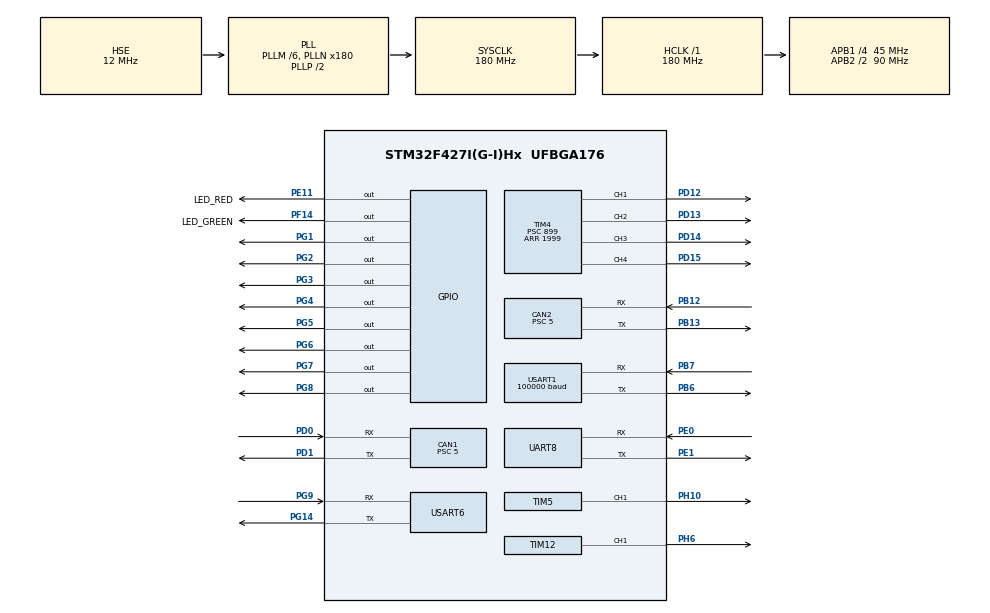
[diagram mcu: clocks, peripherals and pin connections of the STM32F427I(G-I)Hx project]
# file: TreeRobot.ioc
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CAN1.BS1=CAN_BS1_3TQ
CAN1.BS2=CAN_BS2_5TQ
CAN1.CalculateBaudRate=1000000
CAN1.CalculateTimeBit=999.99
CAN1.CalculateTimeQuantum=111.11111111111111
CAN1.Prescaler=5
CAN2.BS1=CAN_BS1_3TQ
CAN2.BS2=CAN_BS2_5TQ
CAN2.CalculateBaudRate=1000000
CAN2.CalculateTimeBit=999.99
CAN2.CalculateTimeQuantum=111.11111111111111
CAN2.Prescaler=5
CAN2.SJW=CAN_SJW_4TQ
Dma.Request0=USART1_RX
Dma.Request1=USART6_RX
Dma.Request2=UART8_RX
Dma.UART8_RX.2.Direction=DMA_PERIPH_TO_MEMORY
Dma.UART8_RX.2.FIFOMode=DMA_FIFOMODE_DISABLE
Dma.UART8_RX.2.Instance=DMA1_Stream6
Dma.UART8_RX.2.MemDataAlignment=DMA_MDATAALIGN_BYTE
Dma.UART8_RX.2.MemInc=DMA_MINC_ENABLE
Dma.UART8_RX.2.Mode=DMA_CIRCULAR
Dma.UART8_RX.2.PeriphDataAlignment=DMA_PDATAALIGN_BYTE
Dma.UART8_RX.2.PeriphInc=DMA_PINC_DISABLE
Dma.UART8_RX.2.Priority=DMA_PRIORITY_LOW
Dma.USART1_RX.0.Direction=DMA_PERIPH_TO_MEMORY
Dma.USART1_RX.0.FIFOMode=DMA_FIFOMODE_DISABLE
Dma.USART1_RX.0.Instance=DMA2_Stream2
Dma.USART1_RX.0.MemDataAlignment=DMA_MDATAALIGN_BYTE
Dma.USART1_RX.0.MemInc=DMA_MINC_ENABLE
Dma.USART1_RX.0.Mode=DMA_CIRCULAR
Dma.USART1_RX.0.PeriphDataAlignment=DMA_PDATAALIGN_BYTE
Dma.USART1_RX.0.PeriphInc=DMA_PINC_DISABLE
Dma.USART1_RX.0.Priority=DMA_PRIORITY_LOW
Dma.USART6_RX.1.Direction=DMA_PERIPH_TO_MEMORY
Dma.USART6_RX.1.FIFOMode=DMA_FIFOMODE_DISABLE
Dma.USART6_RX.1.Instance=DMA2_Stream1
Dma.USART6_RX.1.MemDataAlignment=DMA_MDATAALIGN_BYTE
Dma.USART6_RX.1.MemInc=DMA_MINC_ENABLE
Dma.USART6_RX.1.Mode=DMA_CIRCULAR
Dma.USART6_RX.1.PeriphDataAlignment=DMA_PDATAALIGN_BYTE
Dma.USART6_RX.1.PeriphInc=DMA_PINC_DISABLE
Dma.USART6_RX.1.Priority=DMA_PRIORITY_LOW
FREERTOS.Tasks01=defaultTask,0,128,StartDefaultTask,Default,NULL,Dynamic,NULL,NULL
Mcu.Family=STM32F4
Mcu.Name=STM32F427I(G-I)Hx
Mcu.Package=UFBGA176
NVIC.CAN1_RX0_IRQn=true\:5\:0\:false\:false\:true\:true\:true\:true
NVIC.CAN1_TX_IRQn=true\:5\:0\:false\:false\:true\:true\:true\:true
NVIC.CAN2_RX0_IRQn=true\:5\:0\:false\:false\:true\:true\:true\:true
NVIC.CAN2_TX_IRQn=true\:5\:0\:false\:false\:true\:true\:true\:true
NVIC.DMA1_Stream6_IRQn=true\:5\:0\:false\:false\:true\:true\:false\:true
NVIC.DMA2_Stream1_IRQn=true\:5\:0\:false\:false\:true\:true\:false\:true
NVIC.DMA2_Stream2_IRQn=true\:5\:0\:false\:false\:true\:false\:true\:true
NVIC.PriorityGroup=NVIC_PRIORITYGROUP_4
NVIC.TIM2_IRQn=true\:0\:0\:false\:false\:true\:false\:true\:true
NVIC.TimeBase=TIM2_IRQn
NVIC.TimeBaseIP=TIM2
NVIC.UART8_IRQn=true\:5\:0\:false\:false\:true\:true\:true\:true
NVIC.USART1_IRQn=true\:5\:0\:false\:false\:true\:true\:true\:true
NVIC.USART6_IRQn=true\:5\:0\:false\:false\:true\:true\:true\:true
PA13.Mode=Serial_Wire
PA13.Signal=SYS_JTMS-SWDIO
PA14.Mode=Serial_Wire
PA14.Signal=SYS_JTCK-SWCLK
PB12.Mode=CAN_Activate
PB12.Signal=CAN2_RX
PB13.Mode=CAN_Activate
PB13.Signal=CAN2_TX
PB6.Mode=Asynchronous
PB6.Signal=USART1_TX
PB7.Mode=Asynchronous
PB7.Signal=USART1_RX
PD0.Mode=CAN_Activate
PD0.Signal=CAN1_RX
PD1.Mode=CAN_Activate
PD1.Signal=CAN1_TX
PD12.Signal=S_TIM4_CH1
PD13.Signal=S_TIM4_CH2
PD14.Signal=S_TIM4_CH3
PD15.Signal=S_TIM4_CH4
PE0.Mode=Asynchronous
PE0.Signal=UART8_RX
PE1.Mode=Asynchronous
PE1.Signal=UART8_TX
PE11.GPIO_Label=LED_RED
PE11.Signal=GPIO_Output
PF14.GPIO_Label=LED_GREEN
PF14.Signal=GPIO_Output
PG1.PinState=GPIO_PIN_SET
PG1.Signal=GPIO_Output
PG14.Mode=Asynchronous
PG14.Signal=USART6_TX
PG2.PinState=GPIO_PIN_SET
PG2.Signal=GPIO_Output
PG3.PinState=GPIO_PIN_SET
PG3.Signal=GPIO_Output
PG4.PinState=GPIO_PIN_SET
PG4.Signal=GPIO_Output
PG5.PinState=GPIO_PIN_SET
PG5.Signal=GPIO_Output
PG6.PinState=GPIO_PIN_SET
PG6.Signal=GPIO_Output
PG7.PinState=GPIO_PIN_SET
PG7.Signal=GPIO_Output
PG8.PinState=GPIO_PIN_SET
PG8.Signal=GPIO_Output
PG9.Mode=Asynchronous
PG9.Signal=USART6_RX
PH0/OSC_IN.Mode=HSE-External-Oscillator
PH0/OSC_IN.Signal=RCC_OSC_IN
PH1/OSC_OUT.Mode=HSE-External-Oscillator
PH1/OSC_OUT.Signal=RCC_OSC_OUT
PH10.Signal=S_TIM5_CH1
PH6.Signal=S_TIM12_CH1
ProjectManager.HeapSize=0x200
ProjectManager.StackSize=0x400
ProjectManager.TargetToolchain=MDK-ARM V5
RCC.48MHZClocksFreq_Value=90000000
RCC.AHBFreq_Value=180000000
RCC.APB1CLKDivider=RCC_HCLK_DIV4
RCC.APB1Freq_Value=45000000
RCC.APB1TimFreq_Value=90000000
RCC.APB2CLKDivider=RCC_HCLK_DIV2
RCC.APB2Freq_Value=90000000
RCC.APB2TimFreq_Value=180000000
RCC.CortexFreq_Value=180000000
RCC.HCLKFreq_Value=180000000
RCC.HSE_VALUE=12000000
RCC.HSI_VALUE=16000000
RCC.LSE_VALUE=32768
RCC.PLLM=6
RCC.PLLN=180
RCC.PLLSourceVirtual=RCC_PLLSOURCE_HSE
RCC.SYSCLKFreq_VALUE=180000000
RCC.SYSCLKSource=RCC_SYSCLKSOURCE_PLLCLK
RCC.VCOOutputFreq_Value=360000000
SH.S_TIM12_CH1.0=TIM12_CH1,PWM Generation1 CH1
SH.S_TIM4_CH1.0=TIM4_CH1,PWM Generation1 CH1
SH.S_TIM4_CH2.0=TIM4_CH2,PWM Generation2 CH2
SH.S_TIM4_CH3.0=TIM4_CH3,PWM Generation3 CH3
SH.S_TIM4_CH4.0=TIM4_CH4,PWM Generation4 CH4
SH.S_TIM5_CH1.0=TIM5_CH1,PWM Generation1 CH1
TIM12.Channel-PWM\ Generation1\ CH1=TIM_CHANNEL_1
TIM12.Period=999
TIM12.Prescaler=89
TIM4.Channel-PWM\ Generation1\ CH1=TIM_CHANNEL_1
TIM4.Channel-PWM\ Generation2\ CH2=TIM_CHANNEL_2
TIM4.Channel-PWM\ Generation3\ CH3=TIM_CHANNEL_3
TIM4.Channel-PWM\ Generation4\ CH4=TIM_CHANNEL_4
TIM4.OCMode_PWM-PWM\ Generation1\ CH1=TIM_OCMODE_PWM2
TIM4.OCMode_PWM-PWM\ Generation2\ CH2=TIM_OCMODE_PWM2
TIM4.OCMode_PWM-PWM\ Generation3\ CH3=TIM_OCMODE_PWM2
TIM4.OCMode_PWM-PWM\ Generation4\ CH4=TIM_OCMODE_PWM2
TIM4.Period=1999
TIM4.Prescaler=899
TIM4.Pulse-PWM\ Generation1\ CH1=0
TIM4.Pulse-PWM\ Generation2\ CH2=0
TIM4.Pulse-PWM\ Generation3\ CH3=0
TIM4.Pulse-PWM\ Generation4\ CH4=0
TIM5.Channel-PWM\ Generation1\ CH1=TIM_CHANNEL_1
TIM5.OCMode_PWM-PWM\ Generation1\ CH1=TIM_OCMODE_PWM2
TIM5.Period=1999
TIM5.Prescaler=899
TIM5.Pulse-PWM\ Generation1\ CH1=1999
UART8.VirtualMode=Asynchronous
USART1.BaudRate=100000
USART1.Parity=PARITY_EVEN
USART1.VirtualMode=VM_ASYNC
USART6.VirtualMode=VM_ASYNC
VP_FREERTOS_VS_CMSIS_V1.Mode=CMSIS_V1
VP_SYS_VS_tim2.Mode=TIM2
VP_TIM12_VS_ClockSourceINT.Mode=Internal
VP_TIM4_VS_ClockSourceINT.Mode=Internal
VP_TIM5_VS_ClockSourceINT.Mode=Internal
board=RemoteControl

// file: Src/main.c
/* USER CODE BEGIN Header */
/**
  ******************************************************************************
  * @file           : main.c
  * @brief          : Main program body
  ******************************************************************************
  * @attention
  *
  * <h2><center>&copy; Copyright (c) 2021 STMicroelectronics.
  * All rights reserved.</center></h2>
  *
  * This software component is licensed by ST under Ultimate Liberty license
  * SLA0044, the "License"; You may not use this file except in compliance with
  * the License. You may obtain a copy of the License at:
  *                             www.st.com/SLA0044
  *
  ******************************************************************************
  */
/* USER CODE END Header */
#include "main.h"
#include "cmsis_os.h"
#include "can.h"
#include "dma.h"
#include "tim.h"
#include "usart.h"
#include "gpio.h"

/* USER CODE BEGIN PV */
/* Private variables ---------------------------------------------------------*/

/* USER CODE END PV */

void SystemClock_Config(void);
void MX_FREERTOS_Init(void);
/* USER CODE BEGIN PFP */
/* Private function prototypes -----------------------------------------------*/

/* USER CODE END PFP */

int main(void)
{

  /* MCU Configuration--------------------------------------------------------*/

  /* Reset of all peripherals, Initializes the Flash interface and the Systick. */
  HAL_Init();

  /* Configure the system clock */
  SystemClock_Config();

  /* Initialize all configured peripherals */
  MX_GPIO_Init();
  MX_DMA_Init();
  MX_USART6_UART_Init();
  MX_USART1_UART_Init();
  MX_CAN1_Init();
  MX_CAN2_Init();
  MX_TIM4_Init();
  MX_TIM5_Init();
  MX_UART8_Init();
  MX_TIM12_Init();

  /* Call init function for freertos objects (in freertos.c) */
  MX_FREERTOS_Init();
  /* Start scheduler */
  osKernelStart();

  /* We should never get here as control is now taken by the scheduler */
  /* Infinite loop */
  while (1)
  {

  }
}

void SystemClock_Config(void)
{
  RCC_OscInitTypeDef RCC_OscInitStruct = {0};
  RCC_ClkInitTypeDef RCC_ClkInitStruct = {0};

  /** Configure the main internal regulator output voltage
  */
  __HAL_RCC_PWR_CLK_ENABLE();
  __HAL_PWR_VOLTAGESCALING_CONFIG(PWR_REGULATOR_VOLTAGE_SCALE1);
  /** Initializes the RCC Oscillators according to the specified parameters
  * in the RCC_OscInitTypeDef structure.
  */
  RCC_OscInitStruct.OscillatorType = RCC_OSCILLATORTYPE_HSE;
  RCC_OscInitStruct.HSEState = RCC_HSE_ON;
  RCC_OscInitStruct.PLL.PLLState = RCC_PLL_ON;
  RCC_OscInitStruct.PLL.PLLSource = RCC_PLLSOURCE_HSE;
  RCC_OscInitStruct.PLL.PLLM = 6;
  RCC_OscInitStruct.PLL.PLLN = 180;
  RCC_OscInitStruct.PLL.PLLP = RCC_PLLP_DIV2;
  RCC_OscInitStruct.PLL.PLLQ = 4;
  if (HAL_RCC_OscConfig(&RCC_OscInitStruct) != HAL_OK)
  {
    Error_Handler();
  }
  /** Activate the Over-Drive mode
  */
  if (HAL_PWREx_EnableOverDrive() != HAL_OK)
  {
    Error_Handler();
  }
  /** Initializes the CPU, AHB and APB buses clocks
  */
  RCC_ClkInitStruct.ClockType = RCC_CLOCKTYPE_HCLK|RCC_CLOCKTYPE_SYSCLK
                              |RCC_CLOCKTYPE_PCLK1|RCC_CLOCKTYPE_PCLK2;
  RCC_ClkInitStruct.SYSCLKSource = RCC_SYSCLKSOURCE_PLLCLK;
  RCC_ClkInitStruct.AHBCLKDivider = RCC_SYSCLK_DIV1;
  RCC_ClkInitStruct.APB1CLKDivider = RCC_HCLK_DIV4;
  RCC_ClkInitStruct.APB2CLKDivider = RCC_HCLK_DIV2;

  if (HAL_RCC_ClockConfig(&RCC_ClkInitStruct, FLASH_LATENCY_5) != HAL_OK)
  {
    Error_Handler();
  }
}

 /**
  * @brief  Period elapsed callback in non blocking mode
  * @note   This function is called  when TIM2 interrupt took place, inside
  * HAL_TIM_IRQHandler(). It makes a direct call to HAL_IncTick() to increment
  * a global variable "uwTick" used as application time base.
  * @param  htim : TIM handle
  * @retval None
  */
void HAL_TIM_PeriodElapsedCallback(TIM_HandleTypeDef *htim)
{
  if (htim->Instance == TIM2) {
    HAL_IncTick();
  }
}

void Error_Handler(void)
{
  while (1)
  {
  }
}

/************************ (C) COPYRIGHT STMicroelectronics *****END OF FILE****/

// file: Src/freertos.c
/* USER CODE BEGIN Header */
/**
  ******************************************************************************
  * File Name          : freertos.c
  * Description        : Code for freertos applications
  ******************************************************************************
  * @attention
  *
  * <h2><center>&copy; Copyright (c) 2021 STMicroelectronics.
  * All rights reserved.</center></h2>
  *
  * This software component is licensed by ST under Ultimate Liberty license
  * SLA0044, the "License"; You may not use this file except in compliance with
  * the License. You may obtain a copy of the License at:
  *                             www.st.com/SLA0044
  *
  ******************************************************************************
  */
/* USER CODE END Header */

#include "FreeRTOS.h"
#include "task.h"
#include "main.h"
#include "cmsis_os.h"

/* USER CODE BEGIN Includes */
#include "common.h"
#include "init_task.h"
#include "init_all_peripheral.h"
/* USER CODE END Includes */

osThreadId defaultTaskHandle;

void StartDefaultTask(void const * argument);

void MX_FREERTOS_Init(void); /* (MISRA C 2004 rule 8.1) */

/* GetIdleTaskMemory prototype (linked to static allocation support) */
void vApplicationGetIdleTaskMemory( StaticTask_t **ppxIdleTaskTCBBuffer, StackType_t **ppxIdleTaskStackBuffer, uint32_t *pulIdleTaskStackSize );

/* USER CODE BEGIN GET_IDLE_TASK_MEMORY */
static StaticTask_t xIdleTaskTCBBuffer;
static StackType_t xIdleStack[configMINIMAL_STACK_SIZE];

void vApplicationGetIdleTaskMemory( StaticTask_t **ppxIdleTaskTCBBuffer, StackType_t **ppxIdleTaskStackBuffer, uint32_t *pulIdleTaskStackSize )
{
  *ppxIdleTaskTCBBuffer = &xIdleTaskTCBBuffer;
  *ppxIdleTaskStackBuffer = &xIdleStack[0];
  *pulIdleTaskStackSize = configMINIMAL_STACK_SIZE;
  /* place for user code */
}
/* USER CODE END GET_IDLE_TASK_MEMORY */

void MX_FREERTOS_Init(void) {
  /* USER CODE BEGIN Init */
  Init_All_Peripherals();
  /* USER CODE END Init */

  /* Create the thread(s) */
  /* definition and creation of defaultTask */
  osThreadDef(defaultTask, StartDefaultTask, osPriorityNormal, 0, 128);
  defaultTaskHandle = osThreadCreate(osThread(defaultTask), NULL);

  /* USER CODE BEGIN RTOS_THREADS */
  /* add threads, ... */
  Init_All_Tasks();
  /* USER CODE END RTOS_THREADS */

}

void StartDefaultTask(void const * argument)
{
  while(1)
  {
      osDelay(1);
  }
}

/************************ (C) COPYRIGHT STMicroelectronics *****END OF FILE****/
